# TM4C129ENCPDT register map
File version: 1.0
CPU: CORTEX_M4 1.0, other endian, MPU, FPU, 3 interrupt priority bits
Registers are 32-bit, read-write, reset 0x0 unless marked. A register's access mark holds for its fields unless they carry their own. Offsets are from the block's base; [hi:lo] are bit positions; {n}, {i} and the like mark numbered series.

## PWM0 — PWM register offsets
Base 0x40028000
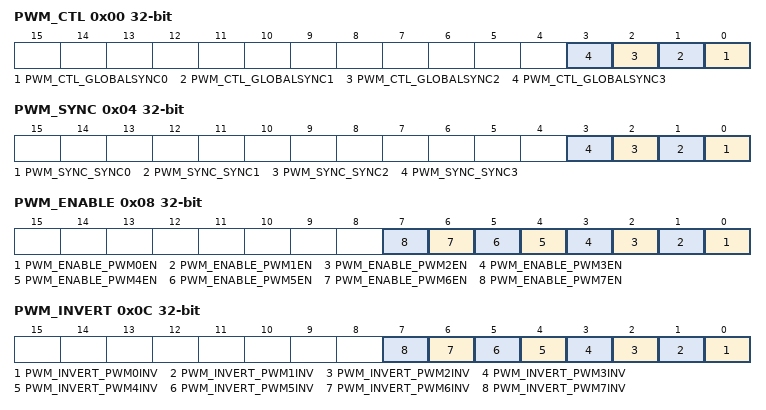
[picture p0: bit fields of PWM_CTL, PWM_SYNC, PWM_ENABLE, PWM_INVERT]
0x00 PWM_CTL — PWM Master Control
  [n] PWM_CTL_GLOBALSYNC{n} (n=0..3) — [{n}:{n}] Update PWM Generator {n}
0x04 PWM_SYNC — PWM Time Base Sync
  [n] PWM_SYNC_SYNC{n} (n=0..3) — [{n}:{n}] Reset Generator {n} Counter
0x08 PWM_ENABLE — PWM Output Enable
  [n] PWM_ENABLE_PWM{n}EN (n=0..7) — [{n}:{n}] MnPWM{n} Output Enable
0x0C PWM_INVERT — PWM Output Inversion
  [n] PWM_INVERT_PWM{n}INV (n=0..7) — [{n}:{n}] Invert MnPWM{n} Signal
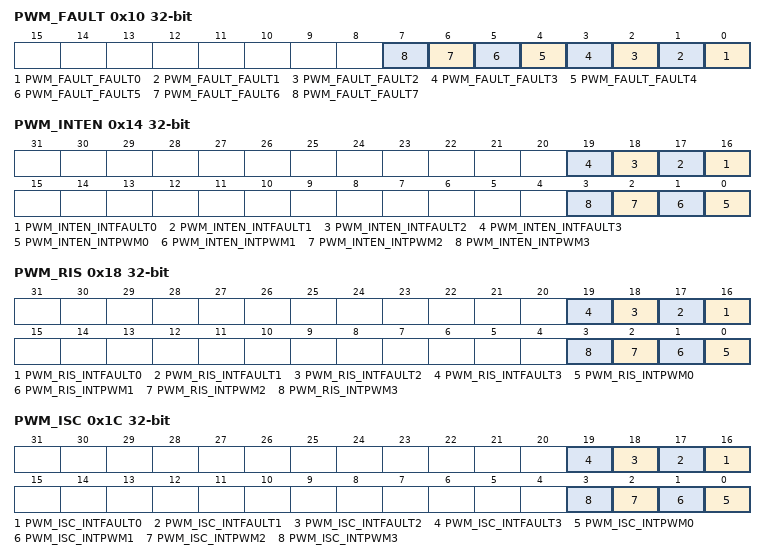
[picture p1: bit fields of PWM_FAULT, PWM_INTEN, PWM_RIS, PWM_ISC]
0x10 PWM_FAULT — PWM Output Fault
  [n] PWM_FAULT_FAULT{n} (n=0..7) — [{n}:{n}] MnPWM{n} Fault
0x14 PWM_INTEN — PWM Interrupt Enable
  [n+16] PWM_INTEN_INTFAULT{n} (n=0..3) — [{n+16}:{n+16}] Interrupt Fault {n}
  [n] PWM_INTEN_INTPWM{n} (n=0..3) — [{n}:{n}] PWM{n} Interrupt Enable
0x18 PWM_RIS — PWM Raw Interrupt Status
  [n+16] PWM_RIS_INTFAULT{n} (n=0..3) — [{n+16}:{n+16}] Interrupt Fault PWM {n}
  [n] PWM_RIS_INTPWM{n} (n=0..3) — [{n}:{n}] PWM{n} Interrupt Asserted
0x1C PWM_ISC — PWM Interrupt Status and Clear
  [n+16] PWM_ISC_INTFAULT{n} (n=0..3) — [{n+16}:{n+16}] FAULT{n} Interrupt Asserted
  [n] PWM_ISC_INTPWM{n} (n=0..3) — [{n}:{n}] PWM{n} Interrupt Status
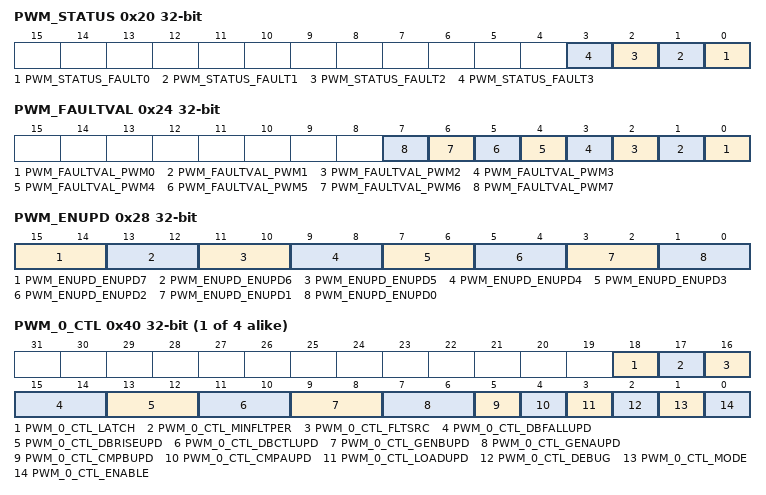
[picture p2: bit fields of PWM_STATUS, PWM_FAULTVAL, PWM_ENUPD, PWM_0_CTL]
0x20 PWM_STATUS
  [n] PWM_STATUS_FAULT{n} (n=0..3) — [{n}:{n}] Generator {n} Fault Status
0x24 PWM_FAULTVAL — PWM Fault Condition Value
  [n] PWM_FAULTVAL_PWM{n} (n=0..7) — [{n}:{n}] MnPWM{n} Fault Value
0x28 PWM_ENUPD — PWM Enable Update
  [15:14] PWM_ENUPD_ENUPD7 — [15:14] MnPWM7 Enable Update Mode
    0=PWM_ENUPD_ENUPD7_IMM (Immediate); 0x8000=PWM_ENUPD_ENUPD7_LSYNC (Locally Synchronized); 0xC000=PWM_ENUPD_ENUPD7_GSYNC (Globally Synchronized)
  [13:12] PWM_ENUPD_ENUPD6 — [13:12] MnPWM6 Enable Update Mode
    0=PWM_ENUPD_ENUPD6_IMM (Immediate); 0x2000=PWM_ENUPD_ENUPD6_LSYNC (Locally Synchronized); 0x3000=PWM_ENUPD_ENUPD6_GSYNC (Globally Synchronized)
  [11:10] PWM_ENUPD_ENUPD5 — [11:10] MnPWM5 Enable Update Mode
    0=PWM_ENUPD_ENUPD5_IMM (Immediate); 0x800=PWM_ENUPD_ENUPD5_LSYNC (Locally Synchronized); 0xC00=PWM_ENUPD_ENUPD5_GSYNC (Globally Synchronized)
  [9:8] PWM_ENUPD_ENUPD4 — [9:8] MnPWM4 Enable Update Mode
    0=PWM_ENUPD_ENUPD4_IMM (Immediate); 0x200=PWM_ENUPD_ENUPD4_LSYNC (Locally Synchronized); 0x300=PWM_ENUPD_ENUPD4_GSYNC (Globally Synchronized)
  [7:6] PWM_ENUPD_ENUPD3 — [7:6] MnPWM3 Enable Update Mode
    0=PWM_ENUPD_ENUPD3_IMM (Immediate); 128=PWM_ENUPD_ENUPD3_LSYNC (Locally Synchronized); 192=PWM_ENUPD_ENUPD3_GSYNC (Globally Synchronized)
  [5:4] PWM_ENUPD_ENUPD2 — [5:4] MnPWM2 Enable Update Mode
    0=PWM_ENUPD_ENUPD2_IMM (Immediate); 32=PWM_ENUPD_ENUPD2_LSYNC (Locally Synchronized); 48=PWM_ENUPD_ENUPD2_GSYNC (Globally Synchronized)
  [3:2] PWM_ENUPD_ENUPD1 — [3:2] MnPWM1 Enable Update Mode
    0=PWM_ENUPD_ENUPD1_IMM (Immediate); 8=PWM_ENUPD_ENUPD1_LSYNC (Locally Synchronized); 12=PWM_ENUPD_ENUPD1_GSYNC (Globally Synchronized)
  [1:0] PWM_ENUPD_ENUPD0 — [1:0] MnPWM0 Enable Update Mode
    0=PWM_ENUPD_ENUPD0_IMM (Immediate); 2=PWM_ENUPD_ENUPD0_LSYNC (Locally Synchronized); 3=PWM_ENUPD_ENUPD0_GSYNC (Globally Synchronized)
{0x40+0x40*i} PWM_{i}_CTL (i=0..3) — PWM{i} Control
  [18] PWM_{i}_CTL_LATCH — [18:18] Latch Fault Input
  [17] PWM_{i}_CTL_MINFLTPER — [17:17] Minimum Fault Period
  [16] PWM_{i}_CTL_FLTSRC — [16:16] Fault Condition Source
  [15:14] PWM_{i}_CTL_DBFALLUPD — [15:14] PWMnDBFALL Update Mode
    0=PWM_{i}_CTL_DBFALLUPD_I (Immediate); 0x8000=PWM_{i}_CTL_DBFALLUPD_LS (Locally Synchronized); 0xC000=PWM_{i}_CTL_DBFALLUPD_GS (Globally Synchronized)
  [13:12] PWM_{i}_CTL_DBRISEUPD — [13:12] PWMnDBRISE Update Mode
    0=PWM_{i}_CTL_DBRISEUPD_I (Immediate); 0x2000=PWM_{i}_CTL_DBRISEUPD_LS (Locally Synchronized); 0x3000=PWM_{i}_CTL_DBRISEUPD_GS (Globally Synchronized)
  [11:10] PWM_{i}_CTL_DBCTLUPD — [11:10] PWMnDBCTL Update Mode
    0=PWM_{i}_CTL_DBCTLUPD_I (Immediate); 0x800=PWM_{i}_CTL_DBCTLUPD_LS (Locally Synchronized); 0xC00=PWM_{i}_CTL_DBCTLUPD_GS (Globally Synchronized)
  [9:8] PWM_{i}_CTL_GENBUPD — [9:8] PWMnGENB Update Mode
    0=PWM_{i}_CTL_GENBUPD_I (Immediate); 0x200=PWM_{i}_CTL_GENBUPD_LS (Locally Synchronized); 0x300=PWM_{i}_CTL_GENBUPD_GS (Globally Synchronized)
  [7:6] PWM_{i}_CTL_GENAUPD — [7:6] PWMnGENA Update Mode
    0=PWM_{i}_CTL_GENAUPD_I (Immediate); 128=PWM_{i}_CTL_GENAUPD_LS (Locally Synchronized); 192=PWM_{i}_CTL_GENAUPD_GS (Globally Synchronized)
  [5] PWM_{i}_CTL_CMPBUPD — [5:5] Comparator B Update Mode
  [4] PWM_{i}_CTL_CMPAUPD — [4:4] Comparator A Update Mode
  [3] PWM_{i}_CTL_LOADUPD — [3:3] Load Register Update Mode
  [2] PWM_{i}_CTL_DEBUG — [2:2] Debug Mode
  [1] PWM_{i}_CTL_MODE — [1:1] Counter Mode
  [0] PWM_{i}_CTL_ENABLE — [0:0] PWM Block Enable
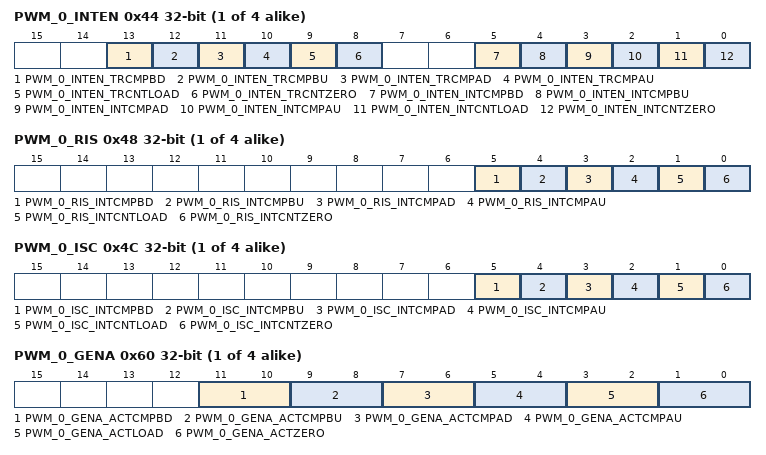
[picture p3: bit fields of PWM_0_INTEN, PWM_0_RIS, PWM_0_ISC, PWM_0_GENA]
{0x44+0x40*i} PWM_{i}_INTEN (i=0..3) — PWM{i} Interrupt and Trigger Enable
  [13] PWM_{i}_INTEN_TRCMPBD — [13:13] Trigger for Counter=PWMnCMPB Down
  [12] PWM_{i}_INTEN_TRCMPBU — [12:12] Trigger for Counter=PWMnCMPB Up
  [11] PWM_{i}_INTEN_TRCMPAD — [11:11] Trigger for Counter=PWMnCMPA Down
  [10] PWM_{i}_INTEN_TRCMPAU — [10:10] Trigger for Counter=PWMnCMPA Up
  [9] PWM_{i}_INTEN_TRCNTLOAD — [9:9] Trigger for Counter=PWMnLOAD
  [8] PWM_{i}_INTEN_TRCNTZERO — [8:8] Trigger for Counter=0
  [5] PWM_{i}_INTEN_INTCMPBD — [5:5] Interrupt for Counter=PWMnCMPB Down
  [4] PWM_{i}_INTEN_INTCMPBU — [4:4] Interrupt for Counter=PWMnCMPB Up
  [3] PWM_{i}_INTEN_INTCMPAD — [3:3] Interrupt for Counter=PWMnCMPA Down
  [2] PWM_{i}_INTEN_INTCMPAU — [2:2] Interrupt for Counter=PWMnCMPA Up
  [1] PWM_{i}_INTEN_INTCNTLOAD — [1:1] Interrupt for Counter=PWMnLOAD
  [0] PWM_{i}_INTEN_INTCNTZERO — [0:0] Interrupt for Counter=0
{0x48+0x40*i} PWM_{i}_RIS (i=0..3) — PWM{i} Raw Interrupt Status
  [5] PWM_{i}_RIS_INTCMPBD — [5:5] Comparator B Down Interrupt Status
  [4] PWM_{i}_RIS_INTCMPBU — [4:4] Comparator B Up Interrupt Status
  [3] PWM_{i}_RIS_INTCMPAD — [3:3] Comparator A Down Interrupt Status
  [2] PWM_{i}_RIS_INTCMPAU — [2:2] Comparator A Up Interrupt Status
  [1] PWM_{i}_RIS_INTCNTLOAD — [1:1] Counter=Load Interrupt Status
  [0] PWM_{i}_RIS_INTCNTZERO — [0:0] Counter=0 Interrupt Status
{0x4C+0x40*i} PWM_{i}_ISC (i=0..3) — PWM{i} Interrupt Status and Clear
  [5] PWM_{i}_ISC_INTCMPBD — [5:5] Comparator B Down Interrupt
  [4] PWM_{i}_ISC_INTCMPBU — [4:4] Comparator B Up Interrupt
  [3] PWM_{i}_ISC_INTCMPAD — [3:3] Comparator A Down Interrupt
  [2] PWM_{i}_ISC_INTCMPAU — [2:2] Comparator A Up Interrupt
  [1] PWM_{i}_ISC_INTCNTLOAD — [1:1] Counter=Load Interrupt
  [0] PWM_{i}_ISC_INTCNTZERO — [0:0] Counter=0 Interrupt
0x50 PWM_0_LOAD
  [15:0] PWM_0_LOAD — [15:0] Counter Load Value
0x54 PWM_0_COUNT — PWM0 Counter
  [15:0] PWM_0_COUNT — [15:0] Counter Value
0x58 PWM_0_CMPA — PWM0 Compare A
  [15:0] PWM_0_CMPA — [15:0] Comparator A Value
0x5C PWM_0_CMPB — PWM0 Compare B
  [15:0] PWM_0_CMPB — [15:0] Comparator B Value
{0x60+0x40*i} PWM_{i}_GENA (i=0..3) — PWM{i} Generator A Control
  [11:10] PWM_{i}_GENA_ACTCMPBD — [11:10] Action for Comparator B Down
    0=PWM_{i}_GENA_ACTCMPBD_NONE (Do nothing); 0x400=PWM_{i}_GENA_ACTCMPBD_INV (Invert pwmA); 0x800=PWM_{i}_GENA_ACTCMPBD_ZERO (Drive pwmA Low); 0xC00=PWM_{i}_GENA_ACTCMPBD_ONE (Drive pwmA High)
  [9:8] PWM_{i}_GENA_ACTCMPBU — [9:8] Action for Comparator B Up
    0=PWM_{i}_GENA_ACTCMPBU_NONE (Do nothing); 0x100=PWM_{i}_GENA_ACTCMPBU_INV (Invert pwmA); 0x200=PWM_{i}_GENA_ACTCMPBU_ZERO (Drive pwmA Low); 0x300=PWM_{i}_GENA_ACTCMPBU_ONE (Drive pwmA High)
  [7:6] PWM_{i}_GENA_ACTCMPAD — [7:6] Action for Comparator A Down
    0=PWM_{i}_GENA_ACTCMPAD_NONE (Do nothing); 64=PWM_{i}_GENA_ACTCMPAD_INV (Invert pwmA); 128=PWM_{i}_GENA_ACTCMPAD_ZERO (Drive pwmA Low); 192=PWM_{i}_GENA_ACTCMPAD_ONE (Drive pwmA High)
  [5:4] PWM_{i}_GENA_ACTCMPAU — [5:4] Action for Comparator A Up
    0=PWM_{i}_GENA_ACTCMPAU_NONE (Do nothing); 16=PWM_{i}_GENA_ACTCMPAU_INV (Invert pwmA); 32=PWM_{i}_GENA_ACTCMPAU_ZERO (Drive pwmA Low); 48=PWM_{i}_GENA_ACTCMPAU_ONE (Drive pwmA High)
  [3:2] PWM_{i}_GENA_ACTLOAD — [3:2] Action for Counter=LOAD
    0=PWM_{i}_GENA_ACTLOAD_NONE (Do nothing); 4=PWM_{i}_GENA_ACTLOAD_INV (Invert pwmA); 8=PWM_{i}_GENA_ACTLOAD_ZERO (Drive pwmA Low); 12=PWM_{i}_GENA_ACTLOAD_ONE (Drive pwmA High)
  [1:0] PWM_{i}_GENA_ACTZERO — [1:0] Action for Counter=0
    0=PWM_{i}_GENA_ACTZERO_NONE (Do nothing); 1=PWM_{i}_GENA_ACTZERO_INV (Invert pwmA); 2=PWM_{i}_GENA_ACTZERO_ZERO (Drive pwmA Low); 3=PWM_{i}_GENA_ACTZERO_ONE (Drive pwmA High)
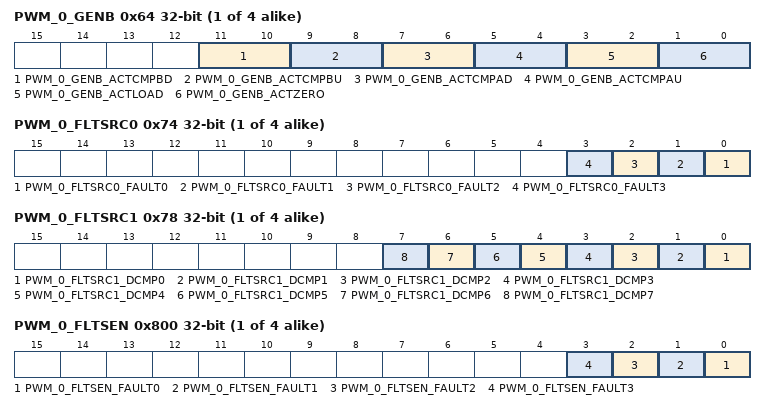
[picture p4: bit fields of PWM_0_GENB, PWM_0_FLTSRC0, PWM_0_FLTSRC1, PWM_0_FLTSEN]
{0x64+0x40*i} PWM_{i}_GENB (i=0..3) — PWM{i} Generator B Control
  [11:10] PWM_{i}_GENB_ACTCMPBD — [11:10] Action for Comparator B Down
    0=PWM_{i}_GENB_ACTCMPBD_NONE (Do nothing); 0x400=PWM_{i}_GENB_ACTCMPBD_INV (Invert pwmB); 0x800=PWM_{i}_GENB_ACTCMPBD_ZERO (Drive pwmB Low); 0xC00=PWM_{i}_GENB_ACTCMPBD_ONE (Drive pwmB High)
  [9:8] PWM_{i}_GENB_ACTCMPBU — [9:8] Action for Comparator B Up
    0=PWM_{i}_GENB_ACTCMPBU_NONE (Do nothing); 0x100=PWM_{i}_GENB_ACTCMPBU_INV (Invert pwmB); 0x200=PWM_{i}_GENB_ACTCMPBU_ZERO (Drive pwmB Low); 0x300=PWM_{i}_GENB_ACTCMPBU_ONE (Drive pwmB High)
  [7:6] PWM_{i}_GENB_ACTCMPAD — [7:6] Action for Comparator A Down
    0=PWM_{i}_GENB_ACTCMPAD_NONE (Do nothing); 64=PWM_{i}_GENB_ACTCMPAD_INV (Invert pwmB); 128=PWM_{i}_GENB_ACTCMPAD_ZERO (Drive pwmB Low); 192=PWM_{i}_GENB_ACTCMPAD_ONE (Drive pwmB High)
  [5:4] PWM_{i}_GENB_ACTCMPAU — [5:4] Action for Comparator A Up
    0=PWM_{i}_GENB_ACTCMPAU_NONE (Do nothing); 16=PWM_{i}_GENB_ACTCMPAU_INV (Invert pwmB); 32=PWM_{i}_GENB_ACTCMPAU_ZERO (Drive pwmB Low); 48=PWM_{i}_GENB_ACTCMPAU_ONE (Drive pwmB High)
  [3:2] PWM_{i}_GENB_ACTLOAD — [3:2] Action for Counter=LOAD
    0=PWM_{i}_GENB_ACTLOAD_NONE (Do nothing); 4=PWM_{i}_GENB_ACTLOAD_INV (Invert pwmB); 8=PWM_{i}_GENB_ACTLOAD_ZERO (Drive pwmB Low); 12=PWM_{i}_GENB_ACTLOAD_ONE (Drive pwmB High)
  [1:0] PWM_{i}_GENB_ACTZERO — [1:0] Action for Counter=0
    0=PWM_{i}_GENB_ACTZERO_NONE (Do nothing); 1=PWM_{i}_GENB_ACTZERO_INV (Invert pwmB); 2=PWM_{i}_GENB_ACTZERO_ZERO (Drive pwmB Low); 3=PWM_{i}_GENB_ACTZERO_ONE (Drive pwmB High)
{0x68+0x40*i} PWM_{i}_DBCTL (i=0..3) — PWM{i} Dead-Band Control
  [0] PWM_{i}_DBCTL_ENABLE — [0:0] Dead-Band Generator Enable
0x6C PWM_0_DBRISE — PWM0 Dead-Band Rising-Edge Delay
  [11:0] PWM_0_DBRISE_DELAY — [11:0] Dead-Band Rise Delay
0x70 PWM_0_DBFALL — PWM0 Dead-Band Falling-Edge-Delay
  [11:0] PWM_0_DBFALL_DELAY — [11:0] Dead-Band Fall Delay
{0x74+0x40*i} PWM_{i}_FLTSRC0 (i=0..3) — PWM{i} Fault Source 0
  [n] PWM_{i}_FLTSRC0_FAULT{n} (n=0..3) — [{n}:{n}] Fault{n} Input
{0x78+0x40*i} PWM_{i}_FLTSRC1 (i=0..3) — PWM{i} Fault Source 1
  [n] PWM_{i}_FLTSRC1_DCMP{n} (n=0..7) — [{n}:{n}] Digital Comparator {n}
0x7C PWM_0_MINFLTPER — PWM0 Minimum Fault Period
  [15:0] PWM_0_MINFLTPER — [15:0] Minimum Fault Period
{0x50+0x40*i} PWM_{i}_LOAD (i=1..3)
  [15:0] PWM_{i}_LOAD_LOAD — [15:0] Counter Load Value
{0x54+0x40*i} PWM_{i}_COUNT (i=1..3) — PWM{i} Counter
  [15:0] PWM_{i}_COUNT_COUNT — [15:0] Counter Value
{0x58+0x40*i} PWM_{i}_CMPA (i=1..3) — PWM{i} Compare A
  [15:0] PWM_{i}_CMPA_COMPA — [15:0] Comparator A Value
{0x5C+0x40*i} PWM_{i}_CMPB (i=1..3) — PWM{i} Compare B
  [15:0] PWM_{i}_CMPB_COMPB — [15:0] Comparator B Value
{0x6C+0x40*i} PWM_{i}_DBRISE (i=1..3) — PWM{i} Dead-Band Rising-Edge Delay
  [11:0] PWM_{i}_DBRISE_RISEDELAY — [11:0] Dead-Band Rise Delay
{0x70+0x40*i} PWM_{i}_DBFALL (i=1..3) — PWM{i} Dead-Band Falling-Edge-Delay
  [11:0] PWM_{i}_DBFALL_FALLDELAY — [11:0] Dead-Band Fall Delay
{0x7C+0x40*i} PWM_{i}_MINFLTPER (i=1..3) — PWM{i} Minimum Fault Period
  [15:0] PWM_{i}_MINFLTPER_MFP — [15:0] Minimum Fault Period
{0x800+0x80*i} PWM_{i}_FLTSEN (i=0..3) — PWM{i} Fault Pin Logic Sense
  [n] PWM_{i}_FLTSEN_FAULT{n} (n=0..3) — [{n}:{n}] Fault{n} Sense
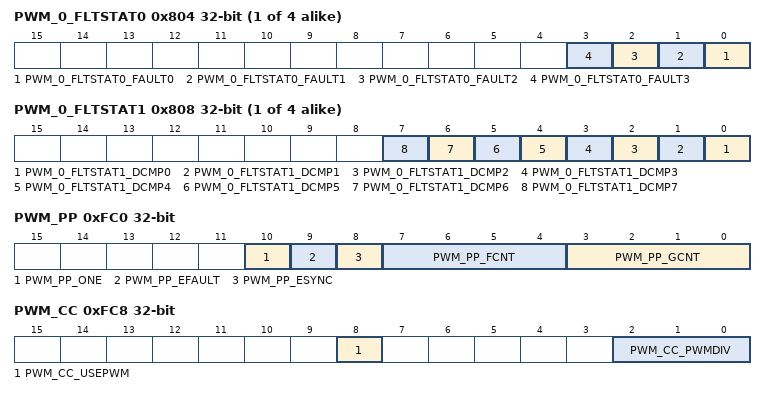
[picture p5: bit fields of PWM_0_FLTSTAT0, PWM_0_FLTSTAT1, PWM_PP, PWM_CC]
{0x804+0x80*i} PWM_{i}_FLTSTAT0 (i=0..3) — PWM{i} Fault Status 0
  [n] PWM_{i}_FLTSTAT0_FAULT{n} (n=0..3) — [{n}:{n}] Fault Input {n}
{0x808+0x80*i} PWM_{i}_FLTSTAT1 (i=0..3) — PWM{i} Fault Status 1
  [n] PWM_{i}_FLTSTAT1_DCMP{n} (n=0..7) — [{n}:{n}] Digital Comparator {n} Trigger
0xFC0 PWM_PP — PWM Peripheral Properties
  [10] PWM_PP_ONE — [10:10] One-Shot Mode
  [9] PWM_PP_EFAULT — [9:9] Extended Fault
  [8] PWM_PP_ESYNC — [8:8] Extended Synchronization
  [7:4] PWM_PP_FCNT — [7:4] Fault Inputs (per PWM unit)
  [3:0] PWM_PP_GCNT — [3:0] Generators
0xFC8 PWM_CC — PWM Clock Configuration
  [8] PWM_CC_USEPWM — [8:8] Use PWM Clock Divisor
  [2:0] PWM_CC_PWMDIV — [2:0] PWM Clock Divider
    0=/2; 1=/4; 2=/8; 3=/16; 4=/32; 5=/64
